# STM32MP21_CM33 register map
File version: 0.4
CPU: CM33 r0p1, little endian, MPU, FPU, vendor SysTick, 8 interrupt priority bits
Registers are 32-bit, read-write, reset 0x0 unless marked. A register's access mark holds for its fields unless they carry their own. Offsets are from the block's base; [hi:lo] are bit positions; {n}, {i} and the like mark numbered series; 'fields as' and 'values as' point back to an identical list.

## CSI — CSI address block description
Base 0x48020000
Same registers: CSI_S 0x58020000
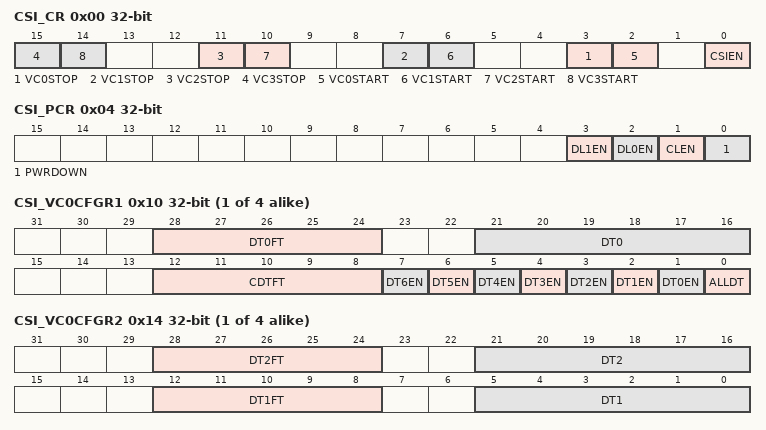
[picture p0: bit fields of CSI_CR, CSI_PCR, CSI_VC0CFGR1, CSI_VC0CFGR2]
0x00 CSI_CR — CSI-2 Host control register
  [4n+3] VC{n}STOP wo (n=0..3) — Virtual channel {n} stop
    0=No effect; 1=Pulse generation to stop the virtual channel {n} processing
  [4n+2] VC{n}START wo (n=0..3) — Virtual channel {n} start
    0=No effect; 1=Pulse generation to start the virtual channel {n} processing
  [0] CSIEN — CSI-2 enable
    0=CSI-2 disabled; 1=CSI-2 enabled
0x04 CSI_PCR — CSI-2 Host DPHY_RX control register
  [3] DL1EN — D-PHY_RX data lane 1 enable
    0=Data lane 1 module is in shutdown mode; 1=Enable the data lane 1 module
  [2] DL0EN — D-PHY_RX data lane 0 enable
    0=Data lane 0 module is in shutdown mode; 1=Enable the data lane 0 module
  [1] CLEN — Clock lane enable
    0=Clock lanes disabled; 1=Clock lanes enabled
  [0] PWRDOWN — Power down
    0=Active state; 1=Power down the D-PHY_RX
{0x10+0x10*i} CSI_VC{i}CFGR1 (i=0..3) — CSI-2 Host virtual channel {i} configuration register 1
  [28:24] DT0FT — Data type 0 format
    0=BPP6 (6-bit words (for example RAW6, RGB666)); 1=BPP7 (7-bit words (for example RAW7)); 2=BPP8 (8-bit words (for example RAW8, YUV 8 bits, RGB888, RGB444, RGB555, RGB565, JPEG)); 3=BPP10 (10-bit words (for example RAW10, YUV 10 bits)); 4=BPP12 (12-bit words (for example RAW12)); 5=BPP14 (14-bit words (for example RAW14)); 6=BPP16 (16-bit words (for example RAW16))
  [21:16] DT0 — Data type 0 class selection for virtual channel x
  [12:8] CDTFT — Common format for all data types
    values as DT0FT
  [n+1] DT{n}EN (n=0..6) — Data type {n} enable
    0=Data type {n} for virtual channel x is disabled; 1=Data type {n} for virtual channel x is enabled
  [0] ALLDT — All data types enable for the virtual channel x
    0=Data type capture managed individually; 1=All data types captured for virtual channel x
{0x14+0x10*i} CSI_VC{i}CFGR2 (i=0..3) — CSI-2 Host virtual channel {i} configuration register 2
  [28:24] DT2FT — Data type 2 format
    values as CSI_VC0CFGR1.DT0FT
  [21:16] DT2 — Data type 2 class selection for virtual channel x
  [12:8] DT1FT — Data type 1 format
    0=BPP6 (6-bit words (for example RAW6, RGB666)); 1=BPP7 (7 -it words (for example RAW7)); 2=BPP8 (8 -it words (for example RAW8, YUV 8 bits, RGB888, RGB444, RGB555, RGB565, JPEG)); 3=BPP10 (10-bit words (for example RAW10, YUV 10 bits)); 4=BPP12 (12 -it words (for example RAW12)); 5=BPP14 (14 -it words (for example RAW14)); 6=BPP16 (16 -it words (for example RAW16))
  [5:0] DT1 — Data type 1 class selection for virtual channel x
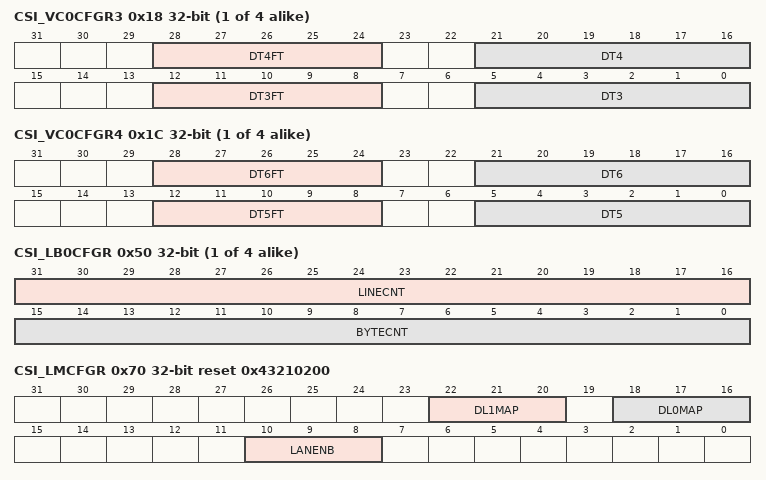
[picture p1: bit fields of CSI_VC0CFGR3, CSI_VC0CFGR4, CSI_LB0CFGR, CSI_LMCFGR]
{0x18+0x10*i} CSI_VC{i}CFGR3 (i=0..3) — CSI-2 Host virtual channel {i} configuration register 3
  [28:24] DT4FT — Data type 4 format
    values as CSI_VC0CFGR1.DT0FT
  [21:16] DT4 — Data type 4 class selection for virtual channel x
  [12:8] DT3FT — Data type 3 format
    values as CSI_VC0CFGR1.DT0FT
  [5:0] DT3 — Data type 3 class selection for virtual channel x
{0x1C+0x10*i} CSI_VC{i}CFGR4 (i=0..3) — CSI-2 Host virtual channel {i} configuration register 4
  [28:24] DT6FT — Data type 6 format
    values as CSI_VC0CFGR1.DT0FT
  [21:16] DT6 — Data type 6 class selection for virtual channel x
  [12:8] DT5FT — Data type 5 format
    values as CSI_VC0CFGR1.DT0FT
  [5:0] DT5 — Data type 5 class selection for virtual channel x
{0x50+4i} CSI_LB{i}CFGR (i=0..3) — CSI-2 Host line byte {i} configuration register
  [31:16] LINECNT — Line counter
  [15:0] BYTECNT — Byte counter
{0x60+4i} CSI_TIM{i}CFGR (i=0..3) — CSI-2 Host timer {i} configuration register
  [24:0] COUNT — Clock cycle counter
0x70 CSI_LMCFGR reset 0x43210200 — CSI-2 Host lane merger configuration register
  [22:20] DL1MAP — Physical mapping of logical data lane 1
    1=Physical data lane 1 connected to logical data lane 0; 2=Physical data lane 1 connected to logical data lane 1
  [18:16] DL0MAP — Physical mapping of logical data lane 0
    1=Physical data lane 0 connected to logical data lane 0; 2=Physical data lane 0 connected to logical data lane 1
  [10:8] LANENB — Number of lanes
    1=1 lane for the reception; 2=2 lanes for the reception
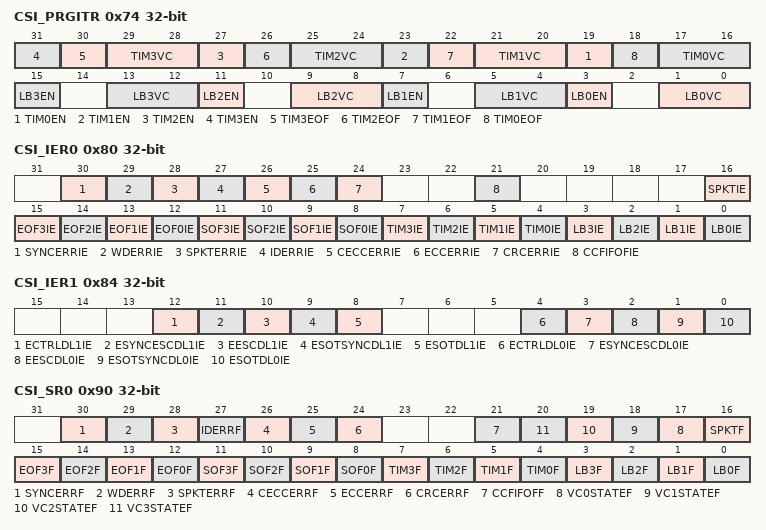
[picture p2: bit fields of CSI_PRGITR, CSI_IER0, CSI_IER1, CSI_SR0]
0x74 CSI_PRGITR — CSI-2 Host program interrupt register
  [4n+19] TIM{n}EN (n=0..3) — TIM{n} base time enable
    0=Timer {n} clock cycle counter not active; 1=Timer {n} clock cycle counter active
  [30] TIM3EOF — TIM3 base time starting from the EOF
    0=SOF selected as starting point for the counter; 1=EOF selected as starting point for the counter
  [4n+17:4n+16] TIM{n}VC (n=0..3) — TIM{n} base time linked to a virtual channel
    {v}=Virtual channel {v} used to generate the TIM{n} event (v=0..3)
  [26] TIM2EOF — TIM2 base time starting from the EOF
    values as TIM3EOF
  [22] TIM1EOF — TIM1 base time starting from the EOF
    values as TIM3EOF
  [18] TIM0EOF — TIM0 base time starting from the EOF
    0=SOF selected e as starting point for the counter; 1=EOF selected as starting point for the counter
  [4n+3] LB{n}EN (n=0..3) — Line/byte {n} counter enable
    0=Line/byte {n} counter stopped; 1=Line/byte {n} counter active
  [4n+1:4n] LB{n}VC (n=0..3) — Line/byte counter {n} linked to a virtual channel
    {v}=Virtual channel {v} used to generate the line/byte counter {n} event (v=0..3)
0x78 CSI_WDR — CSI-2 Host watchdog register
  [31:0] CNT — Watchdog counter
0x80 CSI_IER0 — CSI-2 Host interrupt enable register 0
  [30] SYNCERRIE — Invalid synchronization error interrupt enable
    0=Interrupt on invalid synchronization error disabled; 1=Interrupt on invalid synchronization error enabled
  [29] WDERRIE — Watchdog error interrupt enable
    0=Interrupt on watchdog error disabled; 1=Interrupt on watchdog error enabled
  [28] SPKTERRIE — Short packet error interrupt enable
    0=Interrupt on short packet error disabled; 1=Interrupt on short packet error enabled
  [27] IDERRIE — Data type ID error interrupt enable
    0=Interrupt on reception of reserved data type disabled; 1=Interrupt on reception of reserved data type enabled
  [26] CECCERRIE — Corrected ECC error interrupt enable
    0=Interrupt on corrected ECC error detection disabled; 1=Interrupt on corrected ECC error detection enabled
  [25] ECCERRIE — ECC error interrupt enable
    0=Interrupt on ECC error detection disabled; 1=Interrupt on ECC error detection enabled
  [24] CRCERRIE — CRC error interrupt enable
    0=Interrupt on CRC error detection disabled; 1=Interrupt on CRC error detection enabled
  [21] CCFIFOFIE — Clock changer FIFO full interrupt enable
    0=Interrupt on clock changer FIFO full detection disabled; 1=Interrupt on clock changer FIFO full detection enabled
  [16] SPKTIE — Short packet interrupt enable
    0=Short packet detection interrupt disabled; 1=Short packet detection interrupt enabled
  [n+12] EOF{n}IE (n=0..3) — EOF for virtual channel {n} interrupt enable
    0=EOF on virtual channel {n} interrupt disabled; 1=EOF on virtual channel {n} interrupt enabled
  [n+8] SOF{n}IE (n=0..3) — SOF for virtual channel {n} interrupt enable
    0=SOF on virtual channel {n} interrupt disabled; 1=SOF on virtual channel {n} interrupt enabled
  [n+4] TIM{n}IE (n=0..3) — Timer {n} interrupt enable
    0=Timer {n} interrupt disabled; 1=Timer {n} interrupt enabled
  [n] LB{n}IE (n=0..3) — Line/byte counter {n} interrupt enable
0x84 CSI_IER1 — CSI-2 Host interrupt enable register 1
  [12] ECTRLDL1IE — D-PHY_RX lane 1 control error interrupt enable
    0=Lane 1 control error interrupt disabled; 1=Lane 1 control error interrupt enabled
  [11] ESYNCESCDL1IE — D-PHY_RX lane 1 low-power data transmission synchronization error interrupt enable
    0=Lane 1 low-power data transmission interrupt error disabled; 1=Lane 1 low-power data transmission Interrupt error enabled
  [10] EESCDL1IE — D-PHY_RX lane 1 escape entry error interrupt enable
    0=Lane 1 unrecognized escape entry command interrupt error disabled; 1=Lane 1 unrecognized escape entry command interrupt error enabled
  [9] ESOTSYNCDL1IE — SOT synchronization interrupt error enable on lane 1
    0=Lane 1 SOT synchronization interrupt error disabled; 1=Lane 1 SOT synchronization interrupt error enabled
  [8] ESOTDL1IE — SOT error interrupt enable on lane 1
    0=Lane 1 SOT interrupt error disabled; 1=Lane 1 SOT interrupt error enabled
  [4] ECTRLDL0IE — D-PHY_RX lane 0 control error interrupt enable
    0=Lane 0 control error interrupt disabled; 1=Lane 0 control error interrupt enabled
  [3] ESYNCESCDL0IE — D-PHY_RX lane 0 low power data transmission synchronization error interrupt enable
    0=Lane 0 low-power data transmission interrupt error disabled; 1=Lane 0 low-power data transmission Interrupt error enabled
  [2] EESCDL0IE — D-PHY_RX lane 0 escape entry error interrupt enable
    0=Lane 0 unrecognized escape entry command interrupt error disabled; 1=Lane 0 unrecognized escape entry command interrupt error enabled
  [1] ESOTSYNCDL0IE — SOT synchronization interrupt error enable on lane 0
    0=Lane 0 SOT synchronization interrupt error disabled; 1=Lane 0 SOT synchronization interrupt error enabled
  [0] ESOTDL0IE — SOT error interrupt enable on lane 0
    0=Lane 0 SOT interrupt error disabled; 1=Lane 0 SOT interrupt error enabled
0x90 CSI_SR0 ro — CSI-2 Host status register 0
  [30] SYNCERRF — Invalid synchronization error flag
  [29] WDERRF — Watchdog error flag
  [28] SPKTERRF — Short packet error flag
  [27] IDERRF — Data type ID error flag
  [26] CECCERRF — Corrected ECC error flag
  [25] ECCERRF — ECC error flag
  [24] CRCERRF — CRC error flag
  [21] CCFIFOFF — Clock changer FIFO full flag
  [n+17] VC{n}STATEF (n=0..3) — Virtual channel {n} state flag
    0=Virtual channel inactive; 1=Virtual channel active
  [16] SPKTF — Short packet flag
  [n+12] EOF{n}F (n=0..3) — EOF flag for virtual channel {n}
  [n+8] SOF{n}F (n=0..3) — SOF flag for virtual channel {n}
  [n+4] TIM{n}F (n=0..3) — Timer {n} flag
  [n] LB{n}F (n=0..3) — Line/byte counter {n} flag
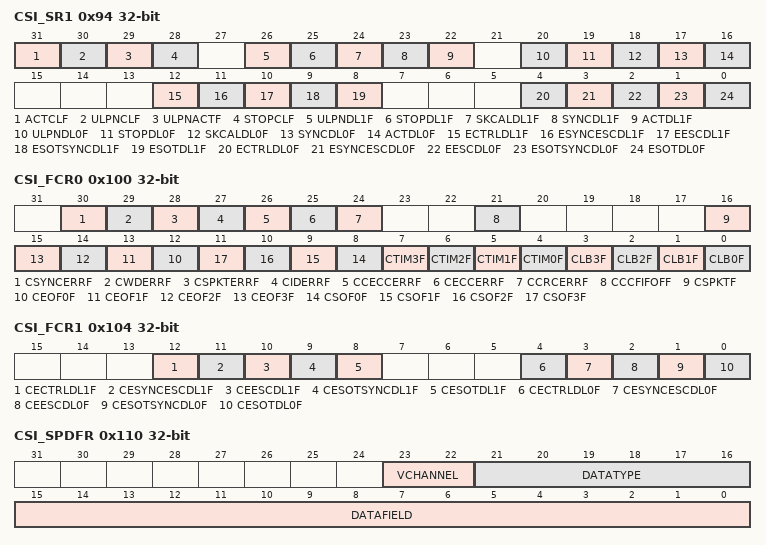
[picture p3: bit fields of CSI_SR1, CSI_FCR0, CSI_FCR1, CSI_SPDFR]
0x94 CSI_SR1 ro — CSI-2 Host status register 1
  [31] ACTCLF — D-PHY_RX receiver clock active flag
  [30] ULPNCLF — D-PHY_RX receiver Ultra-Low power state (not) on clock lane.
  [29] ULPNACTF — D-PHY_RX receiver ULP state (not) active
  [28] STOPCLF — D-PHY_RX receiver in stop state for the clock lane
  [26] ULPNDL1F — D-PHY_RX receiver ultra-low-power state (not) active on data lane 1
  [25] STOPDL1F — D-PHY_RX receiver data lane 1 in stop state
  [24] SKCALDL1F — D-PHY_RX lane 1 high-speed skew calibration
  [23] SYNCDL1F — D-PHY_RX lane 1 receiver synchronization observed
  [22] ACTDL1F — D-PHY_RX lane 1 high-speed reception active
  [20] ULPNDL0F — D-PHY_RX receiver ultra-low-power state (not) active on data lane 0
  [19] STOPDL0F — D-PHY_RX receiver data lane 0 in stop state
  [18] SKCALDL0F — D-PHY_RX lane 0 high-speed skew calibration
  [17] SYNCDL0F — D-PHY_RX lane 0 receiver synchronization observed
  [16] ACTDL0F — D-PHY_RX lane 0 high-speed reception active
  [12] ECTRLDL1F — D-PHY_RX lane 1 control error flag
  [11] ESYNCESCDL1F — D-PHY_RX lane 1 low-power data transmission synchronization error flag
  [10] EESCDL1F — D-PHY_RX lane 1 escape entry error flag
  [9] ESOTSYNCDL1F — SOT synchronization error flag on lane 1
  [8] ESOTDL1F — SOT error flag on lane 1
  [4] ECTRLDL0F — D-PHY_RX lane 0 control error flag
  [3] ESYNCESCDL0F — D-PHY_RX lane 0 low-power data transmission synchronization error flag
  [2] EESCDL0F — D-PHY_RX lane 0 escape entry error flag
  [1] ESOTSYNCDL0F — SOT synchronization error flag on lane 0
  [0] ESOTDL0F — SOT error flag on lane 0
0x100 CSI_FCR0 wo — CSI-2 Host flag clear register 0
  [30] CSYNCERRF — Clear invalid synchronization error flag
  [29] CWDERRF — Clear watchdog error flag
  [28] CSPKTERRF — Clear short packet error flag
  [27] CIDERRF — Clear data type ID error flag
  [26] CCECCERRF — Clear corrected ECC error flag
  [25] CECCERRF — Clear ECC error flag
  [24] CCRCERRF — Clear CRC error flag
  [21] CCCFIFOFF — Clear clock changer FIFO full flag
  [16] CSPKTF — Clear short packet flag
  [n+12] CEOF{n}F (n=0..3) — Clear EOF flag for virtual channel {n}
  [n+8] CSOF{n}F (n=0..3) — Clear SOF flag for virtual channel {n}
  [n+4] CTIM{n}F (n=0..3) — Clear timer {n} flag
  [n] CLB{n}F (n=0..3) — Clear line/byte counter {n} flag
0x104 CSI_FCR1 wo — CSI-2 Host flag clear register 1
  [12] CECTRLDL1F — Clear D-PHY_RX lane 1 control error flag
  [11] CESYNCESCDL1F — Clear D-PHY_RX lane 1 low-power data transmission synchronization error flag
  [10] CEESCDL1F — Clear D-PHY_RX lane 1 escape entry error flag
  [9] CESOTSYNCDL1F — Clear SOT synchronization error flag on lane 1
  [8] CESOTDL1F — Clear SOT error flag on lane 1
  [4] CECTRLDL0F — Clear D-PHY_RX lane 0 control error flag
  [3] CESYNCESCDL0F — Clear D-PHY_RX lane 0 low-power data transmission synchronization error flag
  [2] CEESCDL0F — Clear D-PHY_RX lane 0 escape entry error flag
  [1] CESOTSYNCDL0F — Clear SOT synchronization error flag on lane 0
  [0] CESOTDL0F — Clear SOT error flag on lane 0
0x110 CSI_SPDFR ro — CSI-2 Host short packet data field register
  [23:22] VCHANNEL — Virtual channel
  [21:16] DATATYPE — Data type class
  [15:0] DATAFIELD
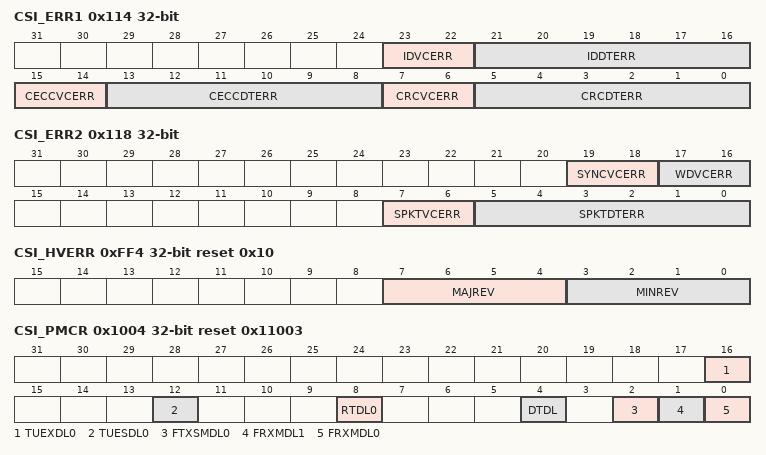
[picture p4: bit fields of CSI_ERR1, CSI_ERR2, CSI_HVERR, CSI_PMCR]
0x114 CSI_ERR1 ro — CSI-2 Host error register 1
  [23:22] IDVCERR — Virtual channel having ID error
  [21:16] IDDTERR — Data type in error
  [15:14] CECCVCERR — Virtual channel having a corrected ECC error
  [13:8] CECCDTERR — Data type having a corrected ECC error
  [7:6] CRCVCERR — Virtual channel having a CRC error
  [5:0] CRCDTERR — Data type having a CRC error
0x118 CSI_ERR2 ro — CSI-2 Host error register 2
  [19:18] SYNCVCERR — Virtual channel having synchronization error
  [17:16] WDVCERR — Virtual channel having a watchdog error
  [7:6] SPKTVCERR — Virtual channel having a short packet error
  [5:0] SPKTDTERR — Data type having a short packet error
0xFF0 CSI_HHWCFGR ro — CSI-2 Host hardware configuration register
  [3:0] TECHNO — Technology
    0=Technology information is not provided; 2=16FF Synopsys PHY
0xFF4 CSI_HVERR ro reset 0x10 — CSI-2 Host version register
  [7:4] MAJREV — Major revision
  [3:0] MINREV — Major revision
0xFF8 CSI_HIPIDR ro reset 0x162011 — CSI-2 Host identification register
  [31:0] ID — Identification code
0xFFC CSI_HSIDR ro reset 0xA3C5DD04 — CSI-2 Host size identification register
  [31:0] SID — Size and ID
0x1000 CSI_PRCR — CSI PHY reset control register
  [1] PEN — When set to 0, this bit places the digital section of the D-PHY in the reset state.
    0=PHY is disabled (in reset state); 1=PHY is enabled (out of reset state)
0x1004 CSI_PMCR reset 0x11003 — CSI PHY mode control register
  [16] TUEXDL0 — Tx ULP exit sequence data lane 0
  [12] TUESDL0 — Tx ULP escape-mode data lane 0
  [8] RTDL0 — Turn-around request data lane 0
    0=No request; 1=Request for turn-around for DL0
  [4] DTDL — Disable turn-around data lane 0
    0=Disabled; 1=Enabled
  [2] FTXSMDL0 — Force to Tx Stop mode the data lane 0
    0=Disabled; 1=Enabled
  [1] FRXMDL1 — Force to Rx mode the data lane 1
    0=Disabled; 1=Enabled
  [0] FRXMDL0 — Force to Rx mode the data lane 0
    0=Disabled; 1=Enabled
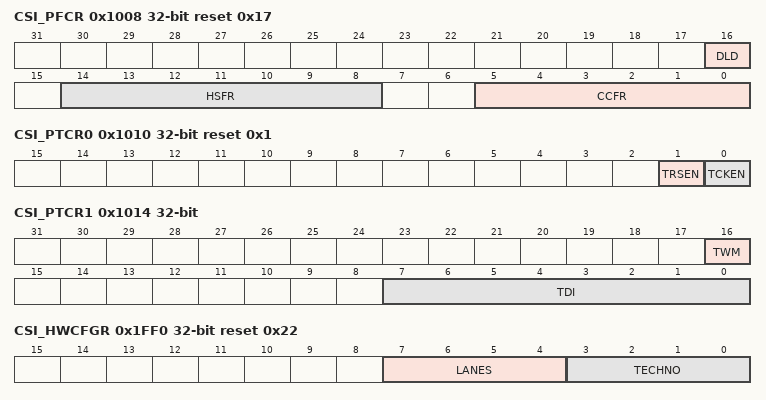
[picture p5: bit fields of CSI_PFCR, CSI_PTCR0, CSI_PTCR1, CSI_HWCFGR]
0x1008 CSI_PFCR reset 0x17 — CSI PHY frequency control register
  [16] DLD — Data lane direction of lane 0
    0=Rx; 1=Tx
  [14:8] HSFR — PHY high-speed frequency range selection
  [5:0] CCFR — Configuration clock frequency range selection
0x1010 CSI_PTCR0 reset 0x1 — CSI PHY test control register 0
  [1] TRSEN — Test-interface reset enable for the TDI bus into the PHY
  [0] TCKEN — Test-interface clock enable for the TDI bus into the PHY
0x1014 CSI_PTCR1 — CSI PHY test control register 1
  [16] TWM — Test-interface write mode selector
    0=Data write operation is set on the rising edge of the testclk signal; 1=Address write operation is set on the falling edge of the testclk signal
  [7:0] TDI — Test-interface data in
0x1018 CSI_PTSR ro — CSI PHY test status register
  [7:0] TDO — CSI PHY test interface data output bus for read-back and internal probing functionalities
0x1FF0 CSI_HWCFGR ro reset 0x22 — CSI-2 Host hardware configuration register
  [7:4] LANES — Amount of CSI data lanes (excluding the clock lane)
    0=Lane information not provided; 1=One CSI data lane implemented; 2=Two CSI data lanes implemented; 4=Four CSI data lanes implemented
  [3:0] TECHNO — Technology
    0=Technology information not provided; 2=16FF Synopsys PHY
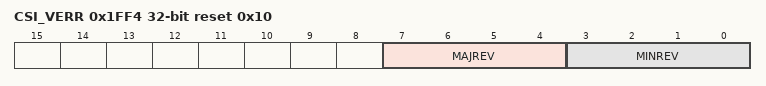
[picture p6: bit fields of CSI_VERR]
0x1FF4 CSI_VERR ro reset 0x10 — CSI-2 Host version register
  [7:4] MAJREV — Major revision
  [3:0] MINREV — Major revision
0x1FF8 CSI_IPIDR ro reset 0x162011 — CSI-2 Host identification register
  [31:0] ID — Identification code
0x1FFC CSI_SIDR ro reset 0xA3C5DD08 — CSI-2 Host size identification register
  [31:0] SID — Size and ID
